AUTOSAR XML (schema 4-3-0)
package /Test_Mode_CDD
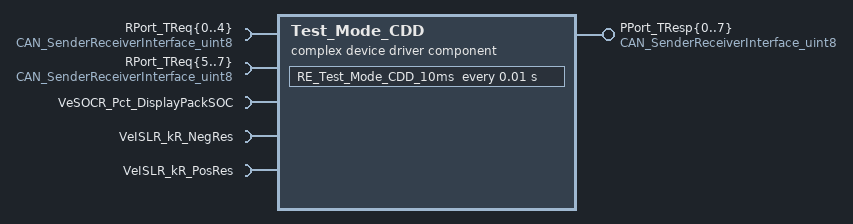
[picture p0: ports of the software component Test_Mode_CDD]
  complex device driver sw component type Test_Mode_CDD
    8 x provide port, all with provided-interface=CAN_SenderReceiverInterface_uint8:
      PPort_TResp{0..7}
    11 x require port:
      RPort_TReq{0..4}: nonqueued-receiver-com-spec{data-element=uint8, enable-update=true}, required-interface=CAN_SenderReceiverInterface_uint8
      RPort_TReq{5..7}: required-interface=CAN_SenderReceiverInterface_uint8
      VeSOCR_Pct_DisplayPackSOC: required-interface=VeSOCR_Pct_DisplayPackSOC
      VeISLR_kR_NegRes: required-interface=VeISLR_kR_NegRes
      VeISLR_kR_PosRes: required-interface=VeISLR_kR_PosRes
    behavior IB_Test_Mode_CDD: data-type-mapping=[SOPR_CodeDataTypeMappingsSet, ISLR_CodeDataTypeMappingsSet]
      timing event TE_Test_Mode_CDD_10ms: start-on-event=RE_Test_Mode_CDD_10ms, period=0.01
      runnable RE_Test_Mode_CDD_10ms
        data-read-access:
          access DRA_VeISLR_kR_NegRes_0: accessed-variable=VeISLR_kR_NegRes.VeISLR_kR_NegRes
          access DRA_VeISLR_kR_PosRes_0: accessed-variable=VeISLR_kR_PosRes.VeISLR_kR_PosRes
          access DRA_VeSOCR_Pct_DisplayPackSOC_0: accessed-variable=VeSOCR_Pct_DisplayPackSOC.VeSOCR_Pct_DisplayPackSOC
        data-receive-point-by-values:
          8 x access:
            DRPV_uint8_0: accessed-variable=RPort_TReq0.uint8
            DRPV_uint8_1: accessed-variable=RPort_TReq2.uint8
            DRPV_uint8_2: accessed-variable=RPort_TReq5.uint8
            DRPV_uint8_3: accessed-variable=RPort_TReq7.uint8
            DRPV_uint8_4: accessed-variable=RPort_TReq3.uint8
            DRPV_uint8_5: accessed-variable=RPort_TReq1.uint8
            DRPV_uint8_6: accessed-variable=RPort_TReq4.uint8
            DRPV_uint8_7: accessed-variable=RPort_TReq6.uint8
        data-send-points:
          8 x access:
            DSP_uint8_0: accessed-variable=PPort_TResp2.uint8
            DSP_uint8_1: accessed-variable=PPort_TResp5.uint8
            DSP_uint8_2: accessed-variable=PPort_TResp3.uint8
            DSP_uint8_3: accessed-variable=PPort_TResp4.uint8
            DSP_uint8_4: accessed-variable=PPort_TResp7.uint8
            DSP_uint8_5: accessed-variable=PPort_TResp1.uint8
            DSP_uint8_6: accessed-variable=PPort_TResp0.uint8
            DSP_uint8_7: accessed-variable=PPort_TResp6.uint8
